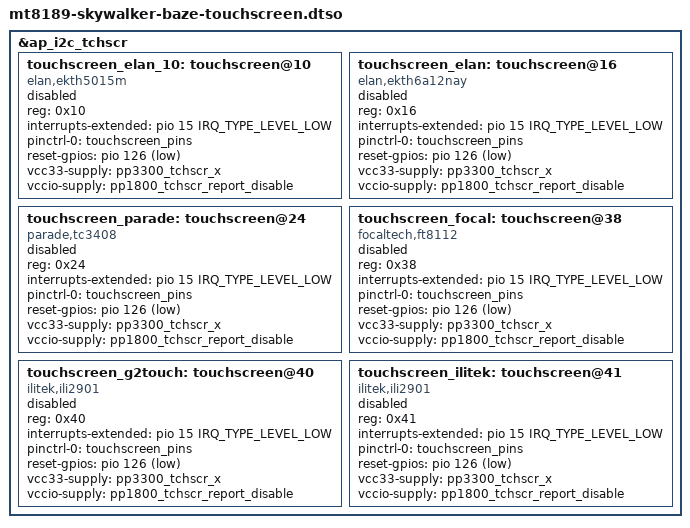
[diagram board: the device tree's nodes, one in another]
// SPDX-License-Identifier: (GPL-2.0 OR MIT)
/*
 * Copyright (C) 2025 Google Inc.
 */
/dts-v1/;
/plugin/;

#include <dt-bindings/gpio/gpio.h>
#include <dt-bindings/interrupt-controller/irq.h>

&ap_i2c_tchscr {
	status = "okay";

	touchscreen_elan_10: touchscreen@10 {
		compatible = "elan,ekth5015m", "elan,ekth6915";
		reg = <0x10>;
		interrupts-extended = <&pio 15 IRQ_TYPE_LEVEL_LOW>;
		pinctrl-names = "default";
		pinctrl-0 = <&touchscreen_pins>;
		reset-gpios = <&pio 126 GPIO_ACTIVE_LOW>;
		vcc33-supply = <&pp3300_tchscr_x>;
		vccio-supply = <&pp1800_tchscr_report_disable>;
		status = "fail-needs-probe";
	};

	touchscreen_elan: touchscreen@16 {
		compatible = "elan,ekth6a12nay";
		reg = <0x16>;
		interrupts-extended = <&pio 15 IRQ_TYPE_LEVEL_LOW>;
		pinctrl-names = "default";
		pinctrl-0 = <&touchscreen_pins>;
		reset-gpios = <&pio 126 GPIO_ACTIVE_LOW>;
		vcc33-supply = <&pp3300_tchscr_x>;
		vccio-supply = <&pp1800_tchscr_report_disable>;
		status = "fail-needs-probe";
	};

	touchscreen_parade: touchscreen@24 {
		compatible = "parade,tc3408";
		reg = <0x24>;
		interrupts-extended = <&pio 15 IRQ_TYPE_LEVEL_LOW>;
		pinctrl-names = "default";
		pinctrl-0 = <&touchscreen_pins>;
		reset-gpios = <&pio 126 GPIO_ACTIVE_LOW>;
		vcc33-supply = <&pp3300_tchscr_x>;
		vccio-supply = <&pp1800_tchscr_report_disable>;
		status = "fail-needs-probe";
	};

	touchscreen_focal: touchscreen@38 {
		compatible = "focaltech,ft8112";
		reg = <0x38>;
		interrupts-extended = <&pio 15 IRQ_TYPE_LEVEL_LOW>;
		pinctrl-names = "default";
		pinctrl-0 = <&touchscreen_pins>;
		reset-gpios = <&pio 126 GPIO_ACTIVE_LOW>;
		vcc33-supply = <&pp3300_tchscr_x>;
		vccio-supply = <&pp1800_tchscr_report_disable>;
		status = "fail-needs-probe";
	};

	touchscreen_g2touch: touchscreen@40 {
		compatible = "ilitek,ili2901";
		reg = <0x40>;
		interrupts-extended = <&pio 15 IRQ_TYPE_LEVEL_LOW>;
		pinctrl-names = "default";
		pinctrl-0 = <&touchscreen_pins>;
		reset-gpios = <&pio 126 GPIO_ACTIVE_LOW>;
		vcc33-supply = <&pp3300_tchscr_x>;
		vccio-supply = <&pp1800_tchscr_report_disable>;
		status = "fail-needs-probe";
	};

	touchscreen_ilitek: touchscreen@41 {
		compatible = "ilitek,ili2901";
		reg = <0x41>;
		interrupts-extended = <&pio 15 IRQ_TYPE_LEVEL_LOW>;
		pinctrl-names = "default";
		pinctrl-0 = <&touchscreen_pins>;
		reset-gpios = <&pio 126 GPIO_ACTIVE_LOW>;
		vcc33-supply = <&pp3300_tchscr_x>;
		vccio-supply = <&pp1800_tchscr_report_disable>;
		status = "fail-needs-probe";
	};
};
